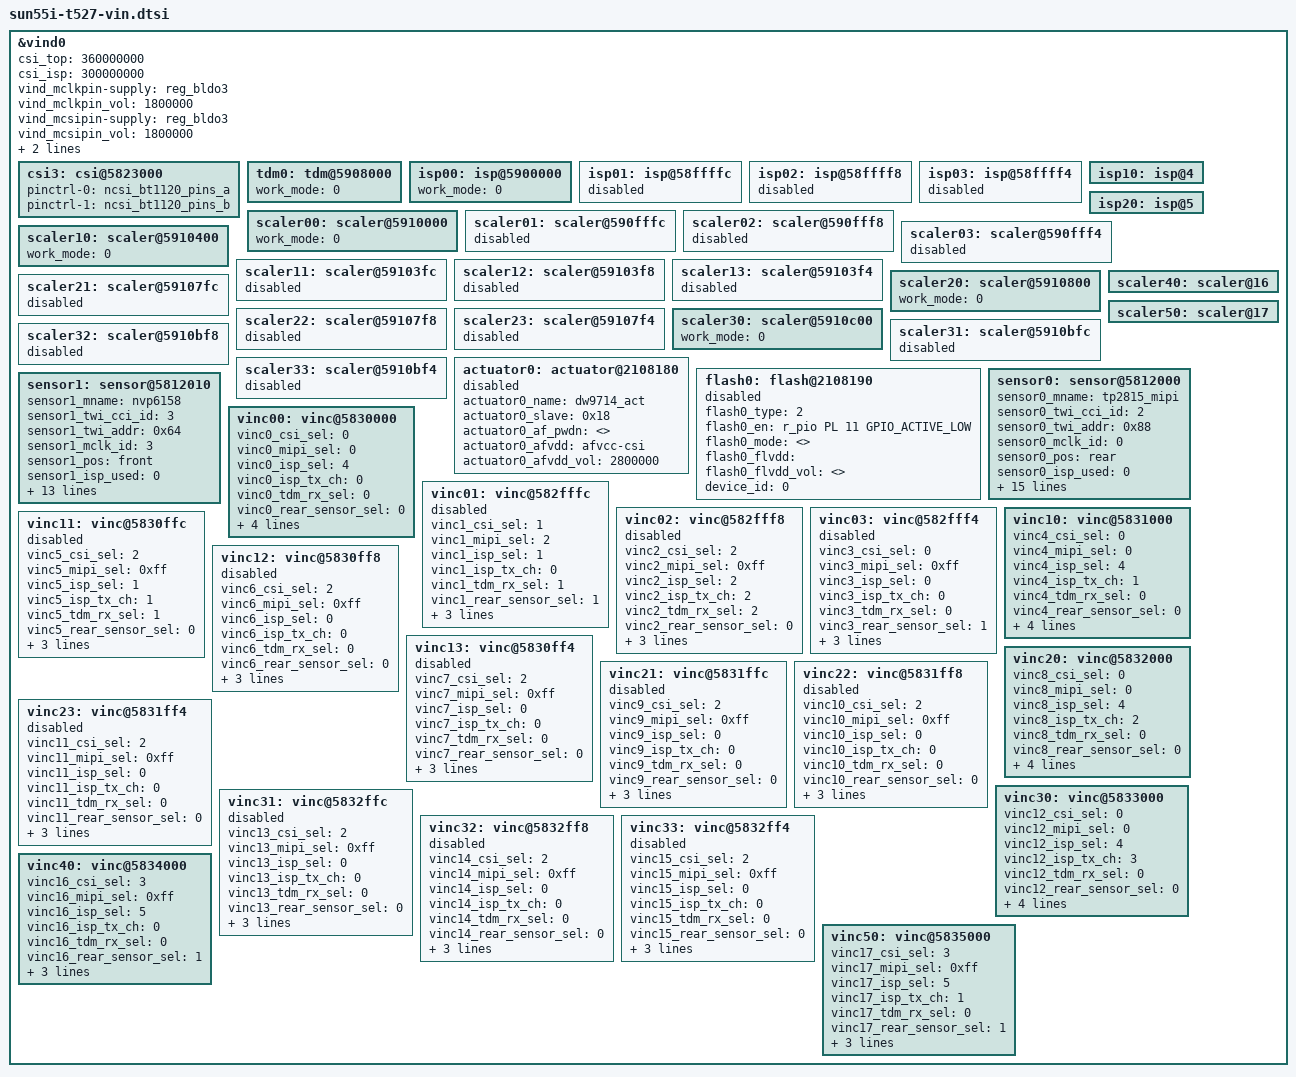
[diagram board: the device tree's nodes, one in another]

&vind0 {
	csi_top = <360000000>;
	csi_isp = <300000000>;
	vind_mclkpin-supply = <&reg_bldo3>; /* vcc-pe */
	vind_mclkpin_vol = <1800000>;
	vind_mcsipin-supply = <&reg_bldo3>; /* vcc-pk */
	vind_mcsipin_vol = <1800000>;
	vind_mipipin-supply = <&reg_bldo3>; /* vcc-mcsi */
	vind_mipipin_vol = <1800000>;
	status = "okay";

	csi3:csi@5823000 {
		pinctrl-names = "default","sleep";
		pinctrl-0 = <&ncsi_bt1120_pins_a>;
		pinctrl-1 = <&ncsi_bt1120_pins_b>;
		status = "okay";
	};

	tdm0:tdm@5908000 {
		work_mode = <0>;
	};

	isp00:isp@5900000 {
		work_mode = <0>;
	};

	isp01:isp@58ffffc {
		status = "disabled";
	};

	isp02:isp@58ffff8 {
		status = "disabled";
	};

	isp03:isp@58ffff4 {
		status = "disabled";
	};

	isp10:isp@4 {
		status = "okay";
	};

	isp20:isp@5 {
		status = "okay";
	};

	scaler00:scaler@5910000 {
		work_mode = <0>;
	};

	scaler01:scaler@590fffc {
		status = "disabled";
	};

	scaler02:scaler@590fff8 {
		status = "disabled";
	};

	scaler03:scaler@590fff4 {
		status = "disabled";
	};

	scaler10:scaler@5910400 {
		work_mode = <0>;
	};

	scaler11:scaler@59103fc {
		status = "disabled";
	};

	scaler12:scaler@59103f8 {
		status = "disabled";
	};

	scaler13:scaler@59103f4 {
		status = "disabled";
	};

	scaler20:scaler@5910800 {
		work_mode = <0>;
	};

	scaler21:scaler@59107fc {
		status = "disabled";
	};

	scaler22:scaler@59107f8 {
		status = "disabled";
	};

	scaler23:scaler@59107f4 {
		status = "disabled";
	};

	scaler30:scaler@5910c00 {
		work_mode = <0>;
	};

	scaler31:scaler@5910bfc {
		status = "disabled";
	};

	scaler32:scaler@5910bf8 {
		status = "disabled";
	};

	scaler33:scaler@5910bf4 {
		status = "disabled";
	};
	scaler40:scaler@16 {
		status = "okay";
	};
	scaler50:scaler@17 {
		status = "okay";
	};

	actuator0: actuator@2108180 {
		device_type = "actuator0";
		actuator0_name = "dw9714_act";
		actuator0_slave = <0x18>;
		actuator0_af_pwdn = <>;
		actuator0_afvdd = "afvcc-csi";
		actuator0_afvdd_vol = <2800000>;
		status = "disabled";
	};

	flash0: flash@2108190 {
		device_type = "flash0";
		flash0_type = <2>;
		flash0_en = <&r_pio PL 11 GPIO_ACTIVE_LOW>;
		flash0_mode = <>;
		flash0_flvdd = "";
		flash0_flvdd_vol = <>;
		device_id = <0>;
		status = "disabled";
	};

	sensor0:sensor@5812000 {
		device_type = "sensor0";
		sensor0_mname = "tp2815_mipi";
		sensor0_twi_cci_id = <2>;
		sensor0_twi_addr = <0x88>;
		sensor0_mclk_id = <0>;
		sensor0_pos = "rear";
		sensor0_isp_used = <0>;
		sensor0_fmt = <0>;
		sensor0_stby_mode = <0>;
		sensor0_vflip = <0>;
		sensor0_hflip = <0>;
		sensor0_cameravdd-supply = <>;
		sensor0_cameravdd_vol = <>;
		sensor0_iovdd-supply = <>;
		sensor0_iovdd_vol = <>;
		sensor0_avdd-supply = <>;
		sensor0_avdd_vol = <>;
		sensor0_dvdd-supply = <>;
		sensor0_dvdd_vol = <>;
		sensor0_power_en = <>;
		sensor0_reset = <&pio PK 11 GPIO_ACTIVE_LOW>;
		sensor0_pwdn = <>;
		status = "okay";
	};

	sensor1:sensor@5812010 {
		device_type = "sensor1";
		sensor1_mname = "nvp6158";
		sensor1_twi_cci_id = <3>;
		sensor1_twi_addr = <0x64>;
		sensor1_mclk_id = <3>;
		sensor1_pos = "front";
		sensor1_isp_used = <0>;
		sensor1_fmt = <0>;
		sensor1_stby_mode = <0>;
		sensor1_vflip = <0>;
		sensor1_hflip = <0>;
		sensor1_iovdd-supply = <>;
		sensor1_iovdd_vol = <>;
		sensor1_avdd-supply = <>;
		sensor1_avdd_vol = <>;
		sensor1_dvdd-supply = <>;
		sensor1_dvdd_vol = <>;
		sensor1_power_en = <>;
		sensor1_reset = <&pio PK 10 GPIO_ACTIVE_LOW>;
		sensor1_pwdn = <>;
		status = "okay";
	};

	vinc00:vinc@5830000 {
		vinc0_csi_sel = <0>;
		vinc0_mipi_sel = <0>;
		vinc0_isp_sel = <4>;
		vinc0_isp_tx_ch = <0>;
		vinc0_tdm_rx_sel = <0>;
		vinc0_rear_sensor_sel = <0>;
		vinc0_front_sensor_sel = <0>;
		vinc0_sensor_list = <0>;
		device_id = <0>;
		work_mode = <0x0>;
		status = "okay";
	};

	vinc01:vinc@582fffc {
		vinc1_csi_sel = <1>;
		vinc1_mipi_sel = <2>;
		vinc1_isp_sel = <1>;
		vinc1_isp_tx_ch = <0>;
		vinc1_tdm_rx_sel = <1>;
		vinc1_rear_sensor_sel = <1>;
		vinc1_front_sensor_sel = <1>;
		vinc1_sensor_list = <0>;
		device_id = <1>;
		status = "disabled";
	};

	vinc02:vinc@582fff8 {
		vinc2_csi_sel = <2>;
		vinc2_mipi_sel = <0xff>;
		vinc2_isp_sel = <2>;
		vinc2_isp_tx_ch = <2>;
		vinc2_tdm_rx_sel = <2>;
		vinc2_rear_sensor_sel = <0>;
		vinc2_front_sensor_sel = <0>;
		vinc2_sensor_list = <0>;
		device_id = <2>;
		status = "disabled";
	};

	vinc03:vinc@582fff4 {
		vinc3_csi_sel = <0>;
		vinc3_mipi_sel = <0xff>;
		vinc3_isp_sel = <0>;
		vinc3_isp_tx_ch = <0>;
		vinc3_tdm_rx_sel = <0>;
		vinc3_rear_sensor_sel = <1>;
		vinc3_front_sensor_sel = <1>;
		vinc3_sensor_list = <0>;
		device_id = <3>;
		status = "disabled";
	};

	vinc10:vinc@5831000 {
		vinc4_csi_sel = <0>;
		vinc4_mipi_sel = <0>;
		vinc4_isp_sel = <4>;
		vinc4_isp_tx_ch = <1>;
		vinc4_tdm_rx_sel = <0>;
		vinc4_rear_sensor_sel = <0>;
		vinc4_front_sensor_sel = <0>;
		vinc4_sensor_list = <0>;
		device_id = <4>;
		work_mode = <0x0>;
		status = "okay";
	};

	vinc11:vinc@5830ffc {
		vinc5_csi_sel = <2>;
		vinc5_mipi_sel = <0xff>;
		vinc5_isp_sel = <1>;
		vinc5_isp_tx_ch = <1>;
		vinc5_tdm_rx_sel = <1>;
		vinc5_rear_sensor_sel = <0>;
		vinc5_front_sensor_sel = <0>;
		vinc5_sensor_list = <0>;
		device_id = <5>;
		status = "disabled";
	};

	vinc12:vinc@5830ff8 {
		vinc6_csi_sel = <2>;
		vinc6_mipi_sel = <0xff>;
		vinc6_isp_sel = <0>;
		vinc6_isp_tx_ch = <0>;
		vinc6_tdm_rx_sel = <0>;
		vinc6_rear_sensor_sel = <0>;
		vinc6_front_sensor_sel = <0>;
		vinc6_sensor_list = <0>;
		device_id = <6>;
		status = "disabled";
	};

	vinc13:vinc@5830ff4 {
		vinc7_csi_sel = <2>;
		vinc7_mipi_sel = <0xff>;
		vinc7_isp_sel = <0>;
		vinc7_isp_tx_ch = <0>;
		vinc7_tdm_rx_sel = <0>;
		vinc7_rear_sensor_sel = <0>;
		vinc7_front_sensor_sel = <0>;
		vinc7_sensor_list = <0>;
		device_id = <7>;
		status = "disabled";
	};

	vinc20:vinc@5832000 {
		vinc8_csi_sel = <0>;
		vinc8_mipi_sel = <0>;
		vinc8_isp_sel = <4>;
		vinc8_isp_tx_ch = <2>;
		vinc8_tdm_rx_sel = <0>;
		vinc8_rear_sensor_sel = <0>;
		vinc8_front_sensor_sel = <0>;
		vinc8_sensor_list = <0>;
		device_id = <8>;
		work_mode = <0x0>;
		status = "okay";
	};

	vinc21:vinc@5831ffc {
		vinc9_csi_sel = <2>;
		vinc9_mipi_sel = <0xff>;
		vinc9_isp_sel = <0>;
		vinc9_isp_tx_ch = <0>;
		vinc9_tdm_rx_sel = <0>;
		vinc9_rear_sensor_sel = <0>;
		vinc9_front_sensor_sel = <0>;
		vinc9_sensor_list = <0>;
		device_id = <9>;
		status = "disabled";
	};

	vinc22:vinc@5831ff8 {
		vinc10_csi_sel = <2>;
		vinc10_mipi_sel = <0xff>;
		vinc10_isp_sel = <0>;
		vinc10_isp_tx_ch = <0>;
		vinc10_tdm_rx_sel = <0>;
		vinc10_rear_sensor_sel = <0>;
		vinc10_front_sensor_sel = <0>;
		vinc10_sensor_list = <0>;
		device_id = <10>;
		status = "disabled";
	};

	vinc23:vinc@5831ff4 {
		vinc11_csi_sel = <2>;
		vinc11_mipi_sel = <0xff>;
		vinc11_isp_sel = <0>;
		vinc11_isp_tx_ch = <0>;
		vinc11_tdm_rx_sel = <0>;
		vinc11_rear_sensor_sel = <0>;
		vinc11_front_sensor_sel = <0>;
		vinc11_sensor_list = <0>;
		device_id = <11>;
		status = "disabled";
	};

	vinc30:vinc@5833000 {
		vinc12_csi_sel = <0>;
		vinc12_mipi_sel = <0>;
		vinc12_isp_sel = <4>;
		vinc12_isp_tx_ch = <3>;
		vinc12_tdm_rx_sel = <0>;
		vinc12_rear_sensor_sel = <0>;
		vinc12_front_sensor_sel = <0>;
		vinc12_sensor_list = <0>;
		device_id = <12>;
		work_mode = <0x0>;
		status = "okay";
	};

	vinc31:vinc@5832ffc {
		vinc13_csi_sel = <2>;
		vinc13_mipi_sel = <0xff>;
		vinc13_isp_sel = <0>;
		vinc13_isp_tx_ch = <0>;
		vinc13_tdm_rx_sel = <0>;
		vinc13_rear_sensor_sel = <0>;
		vinc13_front_sensor_sel = <0>;
		vinc13_sensor_list = <0>;
		device_id = <13>;
		status = "disabled";
	};

	vinc32:vinc@5832ff8 {
		vinc14_csi_sel = <2>;
		vinc14_mipi_sel = <0xff>;
		vinc14_isp_sel = <0>;
		vinc14_isp_tx_ch = <0>;
		vinc14_tdm_rx_sel = <0>;
		vinc14_rear_sensor_sel = <0>;
		vinc14_front_sensor_sel = <0>;
		vinc14_sensor_list = <0>;
		device_id = <14>;
		status = "disabled";
	};

	vinc33:vinc@5832ff4 {
		vinc15_csi_sel = <2>;
		vinc15_mipi_sel = <0xff>;
		vinc15_isp_sel = <0>;
		vinc15_isp_tx_ch = <0>;
		vinc15_tdm_rx_sel = <0>;
		vinc15_rear_sensor_sel = <0>;
		vinc15_front_sensor_sel = <0>;
		vinc15_sensor_list = <0>;
		device_id = <15>;
		status = "disabled";
	};

	vinc40:vinc@5834000 {
		vinc16_csi_sel = <3>;
		vinc16_mipi_sel = <0xff>;
		vinc16_isp_sel = <5>;
		vinc16_isp_tx_ch = <0>;
		vinc16_tdm_rx_sel = <0>;
		vinc16_rear_sensor_sel = <1>;
		vinc16_front_sensor_sel = <1>;
		vinc16_sensor_list = <0>;
		device_id = <16>;
		status = "okay";
	};

	vinc50:vinc@5835000 {
		vinc17_csi_sel = <3>;
		vinc17_mipi_sel = <0xff>;
		vinc17_isp_sel = <5>;
		vinc17_isp_tx_ch = <1>;
		vinc17_tdm_rx_sel = <0>;
		vinc17_rear_sensor_sel = <1>;
		vinc17_front_sensor_sel = <1>;
		vinc17_sensor_list = <0>;
		device_id = <17>;
		status = "okay";
	};
};
